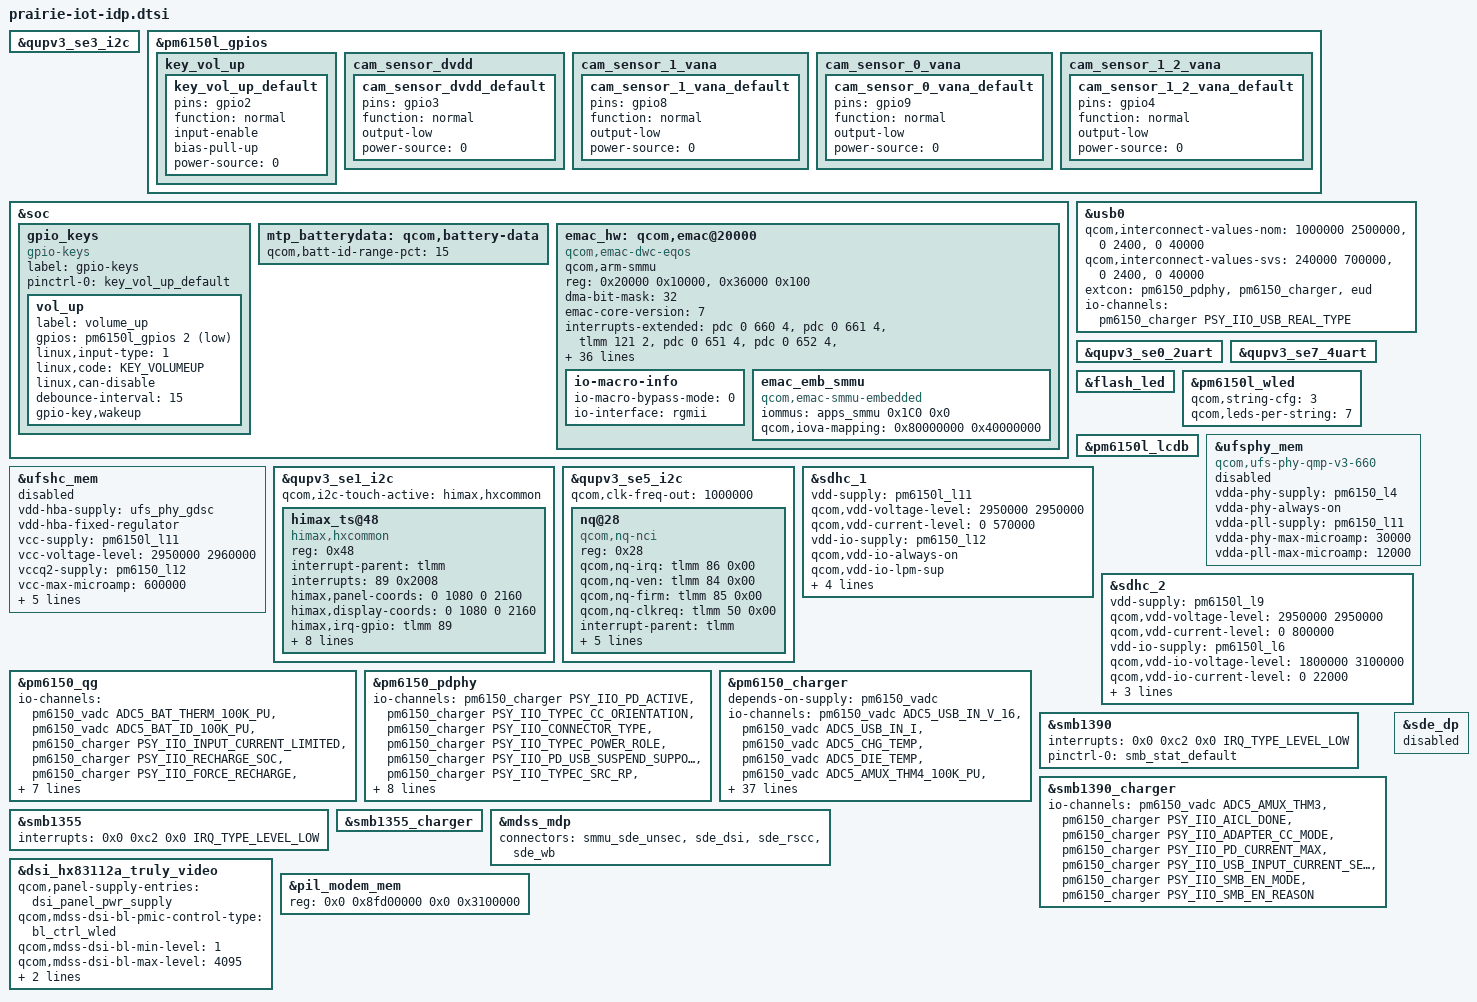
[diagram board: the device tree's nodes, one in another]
#include "sm6150-thermal-overlay.dtsi"
#include <dt-bindings/gpio/gpio.h>
#include <dt-bindings/iio/qcom,spmi-vadc.h>
#include <dt-bindings/input/input.h>
#include "display/sm6150-sde-display.dtsi"
#include <dt-bindings/clock/qcom,gcc-sm6150.h>
#include <dt-bindings/iio/qti_power_supply_iio.h>
#include "camera/sm6150-camera-sensor-idp.dtsi"

&qupv3_se3_i2c {
	#address-cells = <1>;
	#size-cells = <0>;

	status = "ok";
	#include "smb1390.dtsi"
	#include "smb1355.dtsi"
};

&pm6150l_gpios {
	key_vol_up {
		key_vol_up_default: key_vol_up_default {
			pins = "gpio2";
			function = "normal";
			input-enable;
			bias-pull-up;
			power-source = <0>;
		};
	};

	cam_sensor_dvdd {
		cam_sensor_dvdd_default: cam_sensor_dvdd_default {
			pins = "gpio3";
			function = "normal";
			output-low;
			power-source = <0>;
		};
	};

	cam_sensor_1_vana {
		cam_sensor_1_vana_default: cam_sensor_1_vana_default {
			pins = "gpio8";
			function = "normal";
			output-low;
			power-source = <0>;
		};
	};

	cam_sensor_0_vana {
		cam_sensor_0_vana_default: cam_sensor_0_vana_default {
			pins = "gpio9";
			function = "normal";
			output-low;
			power-source = <0>;
		};
	};

	cam_sensor_1_2_vana {
		cam_sensor_1_2_vana_default: cam_sensor_1_2_vana_default {
			pins = "gpio4";
			function = "normal";
			output-low;
			power-source = <0>;
		};
	};

};

&soc {
	gpio_keys {
		compatible = "gpio-keys";
		label = "gpio-keys";

		pinctrl-names = "default";
		pinctrl-0 = <&key_vol_up_default>;

		vol_up {
			label = "volume_up";
			gpios = <&pm6150l_gpios 2 GPIO_ACTIVE_LOW>;
			linux,input-type = <1>;
			linux,code = <KEY_VOLUMEUP>;
			linux,can-disable;
			debounce-interval = <15>;
			gpio-key,wakeup;
		};
	};

	mtp_batterydata: qcom,battery-data {
		qcom,batt-id-range-pct = <15>;
		#include "qg-batterydata-alium-3600mah.dtsi"
		#include "qg-batterydata-mlp356477-2800mah.dtsi"
	};

	emac_hw: qcom,emac@20000 {
		compatible = "qcom,emac-dwc-eqos";
		qcom,arm-smmu;
		reg = <0x20000 0x10000>,
			<0x36000 0x100>;
		reg-names = "emac-base", "rgmii-base";
		dma-bit-mask = <32>;
		emac-core-version = <7>;
		interrupts-extended = <&pdc 0 660 4>, <&pdc 0 661 4>,
			<&tlmm 121 2>, <&pdc 0 651 4>,
			<&pdc 0 652 4>, <&pdc 0 653 4>,
			<&pdc 0 654 4>, <&pdc 0 655 4>,
			<&pdc 0 656 4>, <&pdc 0 657 4>,
			<&pdc 0 658 4>, <&pdc 0 659 4>,
			<&pdc 0 668 4>, <&pdc 0 669 4>;
		interrupt-names = "sbd-intr", "lpi-intr",
			"phy-intr", "tx-ch0-intr",
			"tx-ch1-intr", "tx-ch2-intr",
			"tx-ch3-intr", "tx-ch4-intr",
			"rx-ch0-intr", "rx-ch1-intr",
			"rx-ch2-intr", "rx-ch3-intr",
			"ptp_pps_irq_0","ptp_pps_irq_1";
		qcom,msm-bus,name = "emac";
		qcom,msm-bus,num-cases = <4>;
		qcom,msm-bus,num-paths = <2>;
		qcom,msm-bus,vectors-KBps =
			<98 512 0 0>, <1 781 0 0>,  /* No vote */
			<98 512 1250 0>, <1 781 0 40000>,  /* 10Mbps vote */
			<98 512 12500 0>, <1 781 0 40000>,  /* 100Mbps vote */
			<98 512 125000 0>, <1 781 0 40000>; /* 1000Mbps vote */
		qcom,bus-vector-names = "0", "10", "100", "1000";
		clocks = <&gcc GCC_EMAC_AXI_CLK>,
				<&gcc GCC_EMAC_PTP_CLK>,
				<&gcc GCC_EMAC_RGMII_CLK>,
				<&gcc GCC_EMAC_SLV_AHB_CLK>;
		clock-names = "eth_axi_clk", "eth_ptp_clk",
				"eth_rgmii_clk", "eth_slave_ahb_clk";
		qcom,phy-reset = <&tlmm 104 GPIO_ACTIVE_HIGH>;
		qcom,phy-intr-redirect = <&tlmm 121 GPIO_ACTIVE_LOW>;
		gdsc_emac-supply = <&emac_gdsc>;
		pinctrl-names = "dev-emac-mdc", "dev-emac-mdio",
		"dev-emac-rgmii_txd0_state", "dev-emac-rgmii_txd1_state",
		"dev-emac-rgmii_txd2_state", "dev-emac-rgmii_txd3_state",
		"dev-emac-rgmii_txc_state",  "dev-emac-rgmii_tx_ctl_state",
		"dev-emac-rgmii_rxd0_state", "dev-emac-rgmii_rxd1_state",
		"dev-emac-rgmii_rxd2_state", "dev-emac-rgmii_rxd3_state",
		"dev-emac-rgmii_rxc_state", "dev-emac-rgmii_rx_ctl_state",
		"dev-emac-phy_intr", "dev-emac-phy_reset_state",
		"dev-emac_pin_pps_0";

		pinctrl-0 = <&emac_mdc>;
		pinctrl-1 = <&emac_mdio>;
		pinctrl-2 = <&emac_rgmii_txd0>;
		pinctrl-3 = <&emac_rgmii_txd1>;
		pinctrl-4 = <&emac_rgmii_txd2>;
		pinctrl-5 = <&emac_rgmii_txd3>;
		pinctrl-6 = <&emac_rgmii_txc>;
		pinctrl-7 = <&emac_rgmii_tx_ctl>;
		pinctrl-8 = <&emac_rgmii_rxd0>;
		pinctrl-9 = <&emac_rgmii_rxd1>;
		pinctrl-10 = <&emac_rgmii_rxd2>;
		pinctrl-11 = <&emac_rgmii_rxd3>;
		pinctrl-12 = <&emac_rgmii_rxc>;
		pinctrl-13 = <&emac_rgmii_rx_ctl>;
		pinctrl-14 = <&emac_phy_intr>;
		pinctrl-15 = <&emac_phy_reset_state>;
		pinctrl-16 = <&emac_pin_pps_0>;

		io-macro-info {
			io-macro-bypass-mode = <0>;
			io-interface = "rgmii";
		};

		emac_emb_smmu: emac_emb_smmu {
			compatible = "qcom,emac-smmu-embedded";
			iommus = <&apps_smmu 0x1C0 0x0>;
			qcom,iova-mapping = <0x80000000 0x40000000>;
		};
	};
};

&usb0 {
	qcom,interconnect-values-nom = /* NOMINAL Votes */
						<1000000 2500000>,
						<0 2400>,
						<0 40000>;
	qcom,interconnect-values-svs = /* SVS Votes */
						<240000 700000>,
						<0 2400>,
						<0 40000>;
	extcon = <&pm6150_pdphy>, <&pm6150_charger>, <&eud>;

	#io-channel-cells = <1>;
	io-channels= <&pm6150_charger PSY_IIO_USB_REAL_TYPE>;
	io-channel-names = "chg_type";
};

&qupv3_se0_2uart {
	status = "ok";
};

&qupv3_se7_4uart {
	status = "ok";
};

&flash_led {
	status = "ok";
};

&pm6150l_wled {
	qcom,string-cfg= <3>;
	qcom,leds-per-string = <7>;
	status = "ok";
};

&pm6150l_lcdb {
	status = "ok";
};

&ufsphy_mem {
	compatible = "qcom,ufs-phy-qmp-v3-660";

	vdda-phy-supply = <&pm6150_l4>; /* 0.9v */
	vdda-phy-always-on;
	vdda-pll-supply = <&pm6150_l11>;
	vdda-phy-max-microamp = <30000>;
	vdda-pll-max-microamp = <12000>;

	status="disabled";
};

&ufshc_mem {
	vdd-hba-supply = <&ufs_phy_gdsc>;
	vdd-hba-fixed-regulator;
	vcc-supply = <&pm6150l_l11>;
	vcc-voltage-level = <2950000 2960000>;
	vccq2-supply = <&pm6150_l12>;
	vcc-max-microamp = <600000>;
	vccq2-max-microamp = <600000>;

	qcom,vddp-ref-clk-supply = <&pm6150l_l3>;
	qcom,vddp-ref-clk-max-microamp = <100>;
	qcom,vddp-ref-clk-min-uV = <1232000>;
	qcom,vddp-ref-clk-max-uV = <1260000>;

	status="disabled";
};

&qupv3_se1_i2c {
	#address-cells = <1>;
	#size-cells = <0>;

	status = "ok";
	qcom,i2c-touch-active = "himax,hxcommon";

	himax_ts@48 {
		compatible = "himax,hxcommon";
		reg = <0x48>;
		interrupt-parent = <&tlmm>;
		interrupts = <89 0x2008>;
		himax,panel-coords = <0 1080 0 2160>;
		himax,display-coords = <0 1080 0 2160>;
		himax,irq-gpio = <&tlmm 89 0x00>;
		himax,rst-gpio = <&tlmm 88 0x00>;
		himax,report_type = <1>;

		vdd-supply = <&pm6150_l10>;
		avdd-supply = <&pm6150l_l7>;

		pinctrl-names = "pmx_ts_active","pmx_ts_suspend",
					"pmx_ts_release";
		pinctrl-0 = <&ts_int_active &ts_reset_active>;
		pinctrl-1 = <&ts_int_suspend &ts_reset_suspend>;
		pinctrl-2 = <&ts_release>;

		panel = <&dsi_hx83112a_truly_video>;
	};
};

&qupv3_se5_i2c {
	status = "ok";
	qcom,clk-freq-out = <1000000>;

	#address-cells = <1>;
	#size-cells = <0>;

	nq@28 {
		compatible = "qcom,nq-nci";
		reg = <0x28>;
		qcom,nq-irq = <&tlmm 86 0x00>;
		qcom,nq-ven = <&tlmm 84 0x00>;
		qcom,nq-firm = <&tlmm 85 0x00>;
		qcom,nq-clkreq = <&tlmm 50 0x00>;
		interrupt-parent = <&tlmm>;
		interrupts = <86 0>;
		interrupt-names = "nfc_irq";
		pinctrl-names = "nfc_active", "nfc_suspend";
		pinctrl-0 = <&nfc_int_active &nfc_enable_active
				&nfc_clk_req_active>;
		pinctrl-1 = <&nfc_int_suspend &nfc_enable_suspend
				&nfc_clk_req_suspend>;
	};
};

&sdhc_1 {
	vdd-supply = <&pm6150l_l11>;
	qcom,vdd-voltage-level = <2950000 2950000>;
	qcom,vdd-current-level = <0 570000>;

	vdd-io-supply = <&pm6150_l12>;
	qcom,vdd-io-always-on;
	qcom,vdd-io-lpm-sup;
	qcom,vdd-io-voltage-level = <1800000 1800000>;
	qcom,vdd-io-current-level = <0 325000>;

	pinctrl-names = "active", "sleep";
	pinctrl-0 = <&sdc1_on>;
	pinctrl-1 = <&sdc1_off>;

	status = "ok";
};

&sdhc_2 {
	vdd-supply = <&pm6150l_l9>;
	qcom,vdd-voltage-level = <2950000 2950000>;
	qcom,vdd-current-level = <0 800000>;

	vdd-io-supply = <&pm6150l_l6>;
	qcom,vdd-io-voltage-level = <1800000 3100000>;
	qcom,vdd-io-current-level = <0 22000>;

	pinctrl-names = "active", "sleep";
	pinctrl-0 = <&sdc2_on>;
	pinctrl-1 = <&sdc2_off>;

	cd-gpios = <&tlmm 99 1>;

	status = "ok";
};

&pm6150_qg {
	io-channels = <&pm6150_vadc ADC5_BAT_THERM_100K_PU>,
		      <&pm6150_vadc ADC5_BAT_ID_100K_PU>,
		      <&pm6150_charger PSY_IIO_INPUT_CURRENT_LIMITED>,
		      <&pm6150_charger PSY_IIO_RECHARGE_SOC>,
		      <&pm6150_charger PSY_IIO_FORCE_RECHARGE>,
		      <&pm6150_charger PSY_IIO_CHARGE_DONE>,
		      <&smb1390_charger PSY_IIO_CP_ENABLE>;
	io-channel-names = "batt-therm",
			   "batt-id",
			   "input_current_limited",
			   "recharge_soc",
			   "force_recharge",
			   "charge_done",
			   "cp_charging_enabled";

	qcom,battery-data = <&mtp_batterydata>;
	qcom,qg-iterm-ma = <100>;
	qcom,hold-soc-while-full;
	qcom,linearize-soc;
	qcom,cl-feedback-on;
};

&pm6150_pdphy {
	#io-channel-cells = <1>;
	io-channels = <&pm6150_charger PSY_IIO_PD_ACTIVE>,
		      <&pm6150_charger PSY_IIO_TYPEC_CC_ORIENTATION>,
		      <&pm6150_charger PSY_IIO_CONNECTOR_TYPE>,
		      <&pm6150_charger PSY_IIO_TYPEC_POWER_ROLE>,
		      <&pm6150_charger PSY_IIO_PD_USB_SUSPEND_SUPPORTED>,
		      <&pm6150_charger PSY_IIO_TYPEC_SRC_RP>,
		      <&pm6150_charger PSY_IIO_PD_IN_HARD_RESET>,
		      <&pm6150_charger PSY_IIO_PD_CURRENT_MAX>,
		      <&pm6150_charger PSY_IIO_PR_SWAP>,
		      <&pm6150_charger PSY_IIO_PD_VOLTAGE_MIN>,
		      <&pm6150_charger PSY_IIO_PD_VOLTAGE_MAX>,
		      <&pm6150_charger PSY_IIO_USB_REAL_TYPE>,
		      <&pm6150_charger PSY_IIO_TYPEC_MODE>,
		      <&pm6150_charger PSY_IIO_PE_START>;
	io-channel-names = "pd_active",
			   "typec_cc_orientation",
			   "connector_type",
			   "typec_power_role",
			   "pd_usb_suspend_supported",
			   "typec_src_rp",
			   "pd_in_hard_reset",
			   "pr_current_max",
			   "pr_swap",
			   "pd_voltage_min",
			   "pd_voltage_max",
			   "real_type",
			   "typec_mode",
			   "pe_start";
};

&pm6150_charger {
	depends-on-supply = <&pm6150_vadc>;
	#io-channel-cells = <1>;
	io-channels = <&pm6150_vadc ADC5_USB_IN_V_16>,
		<&pm6150_vadc ADC5_USB_IN_I>,
		<&pm6150_vadc ADC5_CHG_TEMP>,
		<&pm6150_vadc ADC5_DIE_TEMP>,
		<&pm6150_vadc ADC5_AMUX_THM4_100K_PU>,
		<&pm6150_vadc ADC5_SBUx>,
		<&pm6150_vadc ADC5_VPH_PWR>,
		<&pm6150_qg PSY_IIO_CHARGE_FULL>,
		<&pm6150_qg PSY_IIO_CHARGE_FULL_DESIGN>,
		<&pm6150_qg PSY_IIO_RESISTANCE_ID>,
		<&pm6150_qg PSY_IIO_VOLTAGE_NOW>,
		<&pm6150_qg PSY_IIO_TEMP>,
		<&pm6150_qg PSY_IIO_CAPACITY>,
		<&pm6150_qg PSY_IIO_VOLTAGE_OCV>,
		<&pm6150_qg PSY_IIO_VOLTAGE_AVG>,
		<&pm6150_qg PSY_IIO_DEBUG_BATTERY>,
		<&pm6150_qg PSY_IIO_REAL_CAPACITY>,
		<&pm6150_qg PSY_IIO_CC_SOC>,
		<&pm6150_qg PSY_IIO_CURRENT_NOW>,
		<&pm6150_qg PSY_IIO_VOLTAGE_MAX>,
		<&pm6150_qg PSY_IIO_CHARGE_COUNTER>,
		<&pm6150_qg PSY_IIO_CYCLE_COUNT>,
		<&pm6150_qg PSY_IIO_TIME_TO_FULL_NOW>,
		<&smb1390_charger PSY_IIO_PARALLEL_MODE>,
		<&smb1390_charger PSY_IIO_PARALLEL_OUTPUT_MODE>,
		<&smb1390_charger PSY_IIO_MIN_ICL>,
		<&smb1390_charger PSY_IIO_CP_SWITCHER_EN>,
		<&smb1390_charger PSY_IIO_CP_ENABLE>,
		<&smb1390_charger PSY_IIO_CP_ILIM>,
		<&smb1390_charger PSY_IIO_CP_DIE_TEMP>;
	io-channel-names = "usb_in_voltage",
		"usb_in_current",
		"chg_temp",
		"die_temp",
		"conn_temp",
		"sbux_res",
		"vph_voltage",
		"charge_full",
		"charge_full_design",
		"resistance_id",
		"voltage_now",
		"temp",
		"capacity",
		"voltage_ocv",
		"voltage_avg",
		"debug_battery",
		"real_capacity",
		"cc_soc",
		"current_now",
		"voltage_max",
		"charge_counter",
		"cycle_count",
		"time_to_full_now",
		"cp_parallel_mode",
		"cp_parallel_output_mode",
		"cp_min_icl",
		"cp_switcher_en",
		"cp_enable",
		"cp_ilim",
		"cp_die_temp";
	qcom,battery-data = <&mtp_batterydata>;
	qcom,auto-recharge-soc = <98>;
	qcom,step-charging-enable;
	qcom,sw-jeita-enable;
	qcom,fcc-stepping-enable;
	qcom,suspend-input-on-debug-batt;
	qcom,sec-charger-config = <3>;
	qcom,thermal-mitigation = <4200000 3500000 3000000
			2500000 2000000 1500000 1000000 500000>;
	dpdm-supply = <&qusb_phy0>;
	qcom,charger-temp-max = <800>;
	qcom,smb-temp-max = <800>;
};

&smb1390 {
	/delete-property/ interrupts;
	interrupts = <0x0 0xc2 0x0 IRQ_TYPE_LEVEL_LOW>;
	pinctrl-names = "default";
	pinctrl-0 = <&smb_stat_default>;
	status = "ok";
};

&smb1390_charger {
	io-channels = <&pm6150_vadc ADC5_AMUX_THM3>,
		      <&pm6150_charger PSY_IIO_AICL_DONE>,
		      <&pm6150_charger PSY_IIO_ADAPTER_CC_MODE>,
		      <&pm6150_charger PSY_IIO_PD_CURRENT_MAX>,
		      <&pm6150_charger PSY_IIO_USB_INPUT_CURRENT_SETTLED>,
		      <&pm6150_charger PSY_IIO_SMB_EN_MODE>,
		      <&pm6150_charger PSY_IIO_SMB_EN_REASON>;
	io-channel-names = "cp_die_temp",
			   "aicl_done",
			   "adapter_cc_mode",
			   "pd_current_max",
			   "input_current_settled",
			   "smb_en_mode",
			   "smb_en_reason";
	status = "ok";
};

&smb1355 {
	/delete-property/ interrupts;
	interrupts = <0x0 0xc2 0x0 IRQ_TYPE_LEVEL_LOW>;
	status = "ok";
};

&smb1355_charger {
	status = "ok";
};

&sde_dp {
	status="disabled";
};

&mdss_mdp {
	connectors = <&smmu_sde_unsec &sde_dsi &sde_rscc &sde_wb>;
};

&dsi_hx83112a_truly_video {
	qcom,panel-supply-entries = <&dsi_panel_pwr_supply>;
	qcom,mdss-dsi-bl-pmic-control-type = "bl_ctrl_wled";
	qcom,mdss-dsi-bl-min-level = <1>;
	qcom,mdss-dsi-bl-max-level = <4095>;
	qcom,platform-te-gpio = <&tlmm 90 0>;
	qcom,platform-reset-gpio = <&tlmm 91 0>;
};

&pil_modem_mem {
	reg = <0x0 0x8fd00000 0x0 0x3100000>;
};
